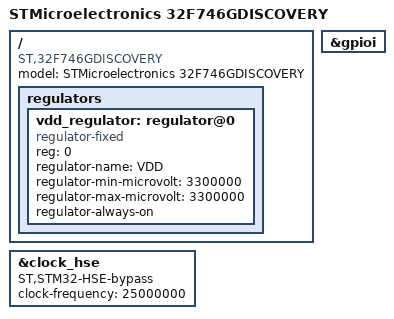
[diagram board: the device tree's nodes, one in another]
/**
 * \file
 * \brief Devicetree for 32F746GDISCOVERY
 *
 * \author Copyright (C) 2017 Kamil Szczygiel http://www.distortec.com http://www.freddiechopin.info
 *
 * \par License
 * This Source Code Form is subject to the terms of the Mozilla Public License, v. 2.0. If a copy of the MPL was not
 * distributed with this file, You can obtain one at http://mozilla.org/MPL/2.0/.
 */

/dts-v1/;

#include "STM32F746NG.dtsi"

/ {
	compatible = "ST,32F746GDISCOVERY", "ST,STM32F746NG";
	model = "STMicroelectronics 32F746GDISCOVERY";

	regulators {
		#address-cells = <1>;
		#size-cells = <0>;

		vdd_regulator: regulator@0 {
			compatible = "regulator-fixed";
			reg = <0>;
			regulator-name = "VDD";
			regulator-min-microvolt = <3300000>;
			regulator-max-microvolt = <3300000>;
			regulator-always-on;
		};
	};
};

&clock_hse {
	ST,STM32-HSE-bypass;
	clock-frequency = <25000000>;
};

&gpioi {
	status = "okay";
};
